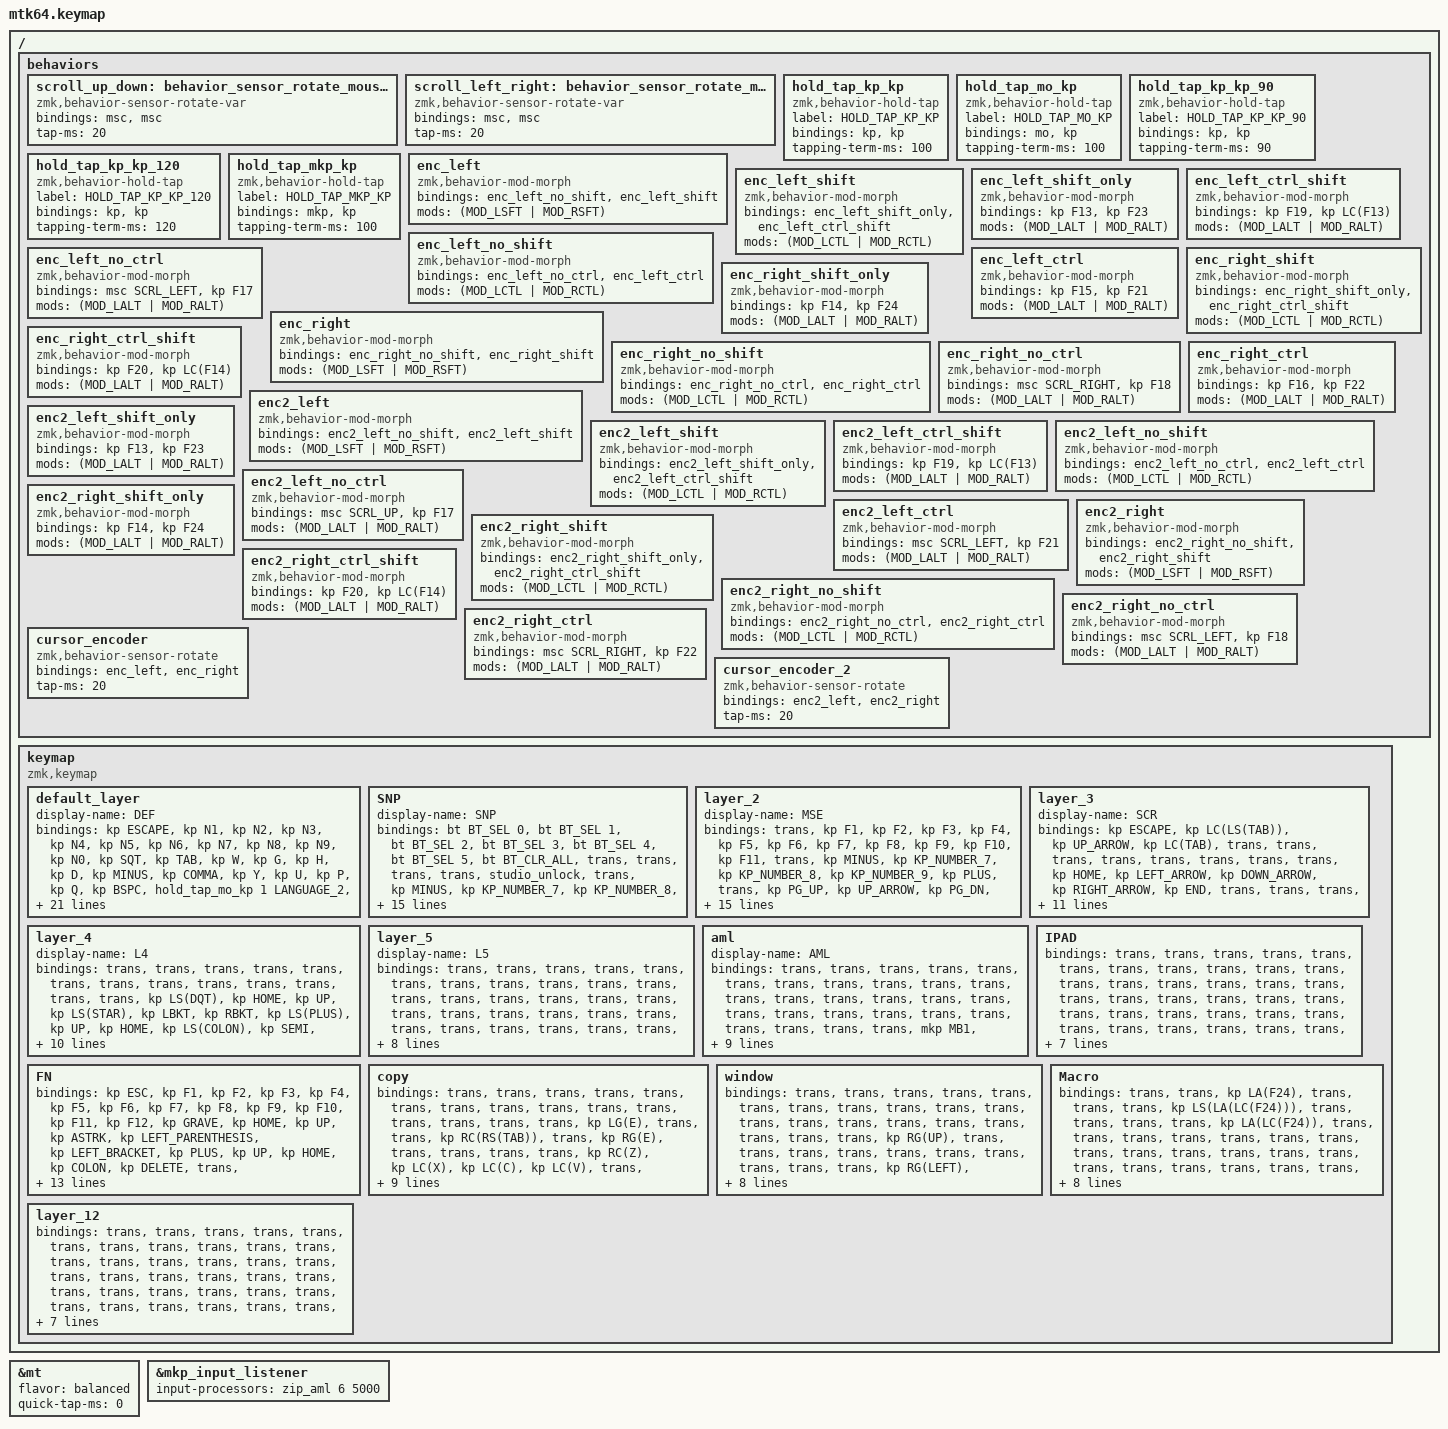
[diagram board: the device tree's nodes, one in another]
#include <input/processors.dtsi>
#include <dt-bindings/zmk/modifiers.h>
#include <behaviors.dtsi>
#include <dt-bindings/zmk/bt.h>
#include <dt-bindings/zmk/keys.h>
#include <dt-bindings/zmk/pointing.h>
#include "keycode_japanese.h"

// スクロール量の設定

#define ZMK_POINTING_DEFAULT_SCRL_VAL 100

&mt {
    flavor = "balanced";
    quick-tap-ms = <0>;
};

&mkp_input_listener { input-processors = <&zip_aml 6 5000>; };

/ {
    behaviors {
        // 垂直スクロール用のbehaviorの設定

        scroll_up_down: behavior_sensor_rotate_mouse_wheel_up_down {
            compatible = "zmk,behavior-sensor-rotate-var";
            #sensor-binding-cells = <2>;
            bindings = <&msc>, <&msc>;

            tap-ms = <20>; // スクロールのタップ時間
        };

        // 水平スクロール用のbehaviorの設定

        scroll_left_right: behavior_sensor_rotate_mouse_wheel_left_right {
            compatible = "zmk,behavior-sensor-rotate-var";
            #sensor-binding-cells = <2>;
            bindings = <&msc>, <&msc>;

            tap-ms = <20>; // スクロールのタップ時間
        };

        hold_tap_kp_kp: hold_tap_kp_kp {
            compatible = "zmk,behavior-hold-tap";
            label = "HOLD_TAP_KP_KP";
            bindings = <&kp>, <&kp>;

            #binding-cells = <2>;
            tapping-term-ms = <100>;
        };

        hold_tap_mo_kp: hold_tap_mo_kp {
            compatible = "zmk,behavior-hold-tap";
            label = "HOLD_TAP_MO_KP";
            bindings = <&mo>, <&kp>;

            #binding-cells = <2>;
            tapping-term-ms = <100>;
        };

        hold_tap_kp_kp_90: hold_tap_kp_kp_90 {
            compatible = "zmk,behavior-hold-tap";
            label = "HOLD_TAP_KP_KP_90";
            bindings = <&kp>, <&kp>;

            #binding-cells = <2>;
            tapping-term-ms = <90>;
        };

        hold_tap_kp_kp_120: hold_tap_kp_kp_120 {
            compatible = "zmk,behavior-hold-tap";
            label = "HOLD_TAP_KP_KP_120";
            bindings = <&kp>, <&kp>;

            #binding-cells = <2>;
            tapping-term-ms = <120>;
        };

        hold_tap_mkp_kp: hold_tap_mkp_kp {
            compatible = "zmk,behavior-hold-tap";
            label = "HOLD_TAP_MKP_KP";
            bindings = <&mkp>, <&kp>;

            #binding-cells = <2>;
            tapping-term-ms = <100>;
        };

        // ==========================================
        // 左エンコーダー
        // ==========================================
        // 左回転

        enc_left: enc_left {
            compatible = "zmk,behavior-mod-morph";
            #binding-cells = <0>;
            bindings = <&enc_left_no_shift>, <&enc_left_shift>;

            mods = <(MOD_LSFT | MOD_RSFT)>;
        };

        enc_left_shift: enc_left_shift {
            compatible = "zmk,behavior-mod-morph";
            #binding-cells = <0>;
            bindings = <&enc_left_shift_only>, <&enc_left_ctrl_shift>;

            mods = <(MOD_LCTL | MOD_RCTL)>;
        };

        enc_left_shift_only: enc_left_shift_only {
            compatible = "zmk,behavior-mod-morph";
            #binding-cells = <0>;
            bindings = <&kp F13>, <&kp F23>;

            mods = <(MOD_LALT | MOD_RALT)>;
        };

        enc_left_ctrl_shift: enc_left_ctrl_shift {
            compatible = "zmk,behavior-mod-morph";
            #binding-cells = <0>;
            bindings = <&kp F19>, <&kp LC(F13)>;

            mods = <(MOD_LALT | MOD_RALT)>;
        };

        enc_left_no_shift: enc_left_no_shift {
            compatible = "zmk,behavior-mod-morph";
            #binding-cells = <0>;
            bindings = <&enc_left_no_ctrl>, <&enc_left_ctrl>;

            mods = <(MOD_LCTL | MOD_RCTL)>;
        };

        enc_left_no_ctrl: enc_left_no_ctrl {
            compatible = "zmk,behavior-mod-morph";
            #binding-cells = <0>;
            bindings = <&msc SCRL_LEFT>, <&kp F17>;

            mods = <(MOD_LALT | MOD_RALT)>;
        };

        enc_left_ctrl: enc_left_ctrl {
            compatible = "zmk,behavior-mod-morph";
            #binding-cells = <0>;
            bindings = <&kp F15>, <&kp F21>;

            mods = <(MOD_LALT | MOD_RALT)>;
        };

        // 右回転

        enc_right: enc_right {
            compatible = "zmk,behavior-mod-morph";
            #binding-cells = <0>;
            bindings = <&enc_right_no_shift>, <&enc_right_shift>;

            mods = <(MOD_LSFT | MOD_RSFT)>;
        };

        enc_right_shift: enc_right_shift {
            compatible = "zmk,behavior-mod-morph";
            #binding-cells = <0>;
            bindings = <&enc_right_shift_only>, <&enc_right_ctrl_shift>;

            mods = <(MOD_LCTL | MOD_RCTL)>;
        };

        enc_right_shift_only: enc_right_shift_only {
            compatible = "zmk,behavior-mod-morph";
            #binding-cells = <0>;
            bindings = <&kp F14>, <&kp F24>;

            mods = <(MOD_LALT | MOD_RALT)>;
        };

        enc_right_ctrl_shift: enc_right_ctrl_shift {
            compatible = "zmk,behavior-mod-morph";
            #binding-cells = <0>;
            bindings = <&kp F20>, <&kp LC(F14)>;

            mods = <(MOD_LALT | MOD_RALT)>;
        };

        enc_right_no_shift: enc_right_no_shift {
            compatible = "zmk,behavior-mod-morph";
            #binding-cells = <0>;
            bindings = <&enc_right_no_ctrl>, <&enc_right_ctrl>;

            mods = <(MOD_LCTL | MOD_RCTL)>;
        };

        enc_right_no_ctrl: enc_right_no_ctrl {
            compatible = "zmk,behavior-mod-morph";
            #binding-cells = <0>;
            bindings = <&msc SCRL_RIGHT>, <&kp F18>;

            mods = <(MOD_LALT | MOD_RALT)>;
        };

        enc_right_ctrl: enc_right_ctrl {
            compatible = "zmk,behavior-mod-morph";
            #binding-cells = <0>;
            bindings = <&kp F16>, <&kp F22>;

            mods = <(MOD_LALT | MOD_RALT)>;
        };

        // ==========================================
        // 右エンコーダー
        // ==========================================
        // 左回転

        enc2_left: enc2_left {
            compatible = "zmk,behavior-mod-morph";
            #binding-cells = <0>;
            bindings = <&enc2_left_no_shift>, <&enc2_left_shift>;

            mods = <(MOD_LSFT | MOD_RSFT)>;
        };

        enc2_left_shift: enc2_left_shift {
            compatible = "zmk,behavior-mod-morph";
            #binding-cells = <0>;
            bindings = <&enc2_left_shift_only>, <&enc2_left_ctrl_shift>;

            mods = <(MOD_LCTL | MOD_RCTL)>;
        };

        enc2_left_shift_only: enc2_left_shift_only {
            compatible = "zmk,behavior-mod-morph";
            #binding-cells = <0>;
            bindings = <&kp F13>, <&kp F23>;

            mods = <(MOD_LALT | MOD_RALT)>;
        };

        enc2_left_ctrl_shift: enc2_left_ctrl_shift {
            compatible = "zmk,behavior-mod-morph";
            #binding-cells = <0>;
            bindings = <&kp F19>, <&kp LC(F13)>;

            mods = <(MOD_LALT | MOD_RALT)>;
        };

        enc2_left_no_shift: enc2_left_no_shift {
            compatible = "zmk,behavior-mod-morph";
            #binding-cells = <0>;
            bindings = <&enc2_left_no_ctrl>, <&enc2_left_ctrl>;

            mods = <(MOD_LCTL | MOD_RCTL)>;
        };

        enc2_left_no_ctrl: enc2_left_no_ctrl {
            compatible = "zmk,behavior-mod-morph";
            #binding-cells = <0>;
            bindings = <&msc SCRL_UP>, <&kp F17>;

            mods = <(MOD_LALT | MOD_RALT)>;
        };

        enc2_left_ctrl: enc2_left_ctrl {
            compatible = "zmk,behavior-mod-morph";
            #binding-cells = <0>;
            bindings = <&msc SCRL_LEFT>, <&kp F21>;

            mods = <(MOD_LALT | MOD_RALT)>;
        };

        // 右回転

        enc2_right: enc2_right {
            compatible = "zmk,behavior-mod-morph";
            #binding-cells = <0>;
            bindings = <&enc2_right_no_shift>, <&enc2_right_shift>;

            mods = <(MOD_LSFT | MOD_RSFT)>;
        };

        enc2_right_shift: enc2_right_shift {
            compatible = "zmk,behavior-mod-morph";
            #binding-cells = <0>;
            bindings = <&enc2_right_shift_only>, <&enc2_right_ctrl_shift>;

            mods = <(MOD_LCTL | MOD_RCTL)>;
        };

        enc2_right_shift_only: enc2_right_shift_only {
            compatible = "zmk,behavior-mod-morph";
            #binding-cells = <0>;
            bindings = <&kp F14>, <&kp F24>;

            mods = <(MOD_LALT | MOD_RALT)>;
        };

        enc2_right_ctrl_shift: enc2_right_ctrl_shift {
            compatible = "zmk,behavior-mod-morph";
            #binding-cells = <0>;
            bindings = <&kp F20>, <&kp LC(F14)>;

            mods = <(MOD_LALT | MOD_RALT)>;
        };

        enc2_right_no_shift: enc2_right_no_shift {
            compatible = "zmk,behavior-mod-morph";
            #binding-cells = <0>;
            bindings = <&enc2_right_no_ctrl>, <&enc2_right_ctrl>;

            mods = <(MOD_LCTL | MOD_RCTL)>;
        };

        enc2_right_no_ctrl: enc2_right_no_ctrl {
            compatible = "zmk,behavior-mod-morph";
            #binding-cells = <0>;
            bindings = <&msc SCRL_LEFT>, <&kp F18>;

            mods = <(MOD_LALT | MOD_RALT)>;
        };

        enc2_right_ctrl: enc2_right_ctrl {
            compatible = "zmk,behavior-mod-morph";
            #binding-cells = <0>;
            bindings = <&msc SCRL_RIGHT>, <&kp F22>;

            mods = <(MOD_LALT | MOD_RALT)>;
        };

        // ==========================================
        // エンコーダー回転の割り当て
        // ==========================================

        cursor_encoder: cursor_encoder {
            compatible = "zmk,behavior-sensor-rotate";
            #sensor-binding-cells = <0>;
            bindings = <&enc_left>, <&enc_right>;

            tap-ms = <20>;
        };

        cursor_encoder_2: cursor_encoder_2 {
            compatible = "zmk,behavior-sensor-rotate";
            #sensor-binding-cells = <0>;
            bindings = <&enc2_left>, <&enc2_right>;

            tap-ms = <20>;
        };

        //ここまで
    };
};

/ {
    keymap {
        compatible = "zmk,keymap";

        default_layer {
            display-name = "DEF";
            bindings = <
&kp ESCAPE  &kp N1  &kp N2  &kp N3  &kp N4  &kp N5  &kp N6  &kp N7  &kp N8  &kp N9  &kp N0  &kp SQT  &kp TAB  &kp W  &kp G  &kp H  &kp D  &kp MINUS  &kp COMMA  &kp Y  &kp U  &kp P  &kp Q  &kp BSPC  &hold_tap_mo_kp 1 LANGUAGE_2  &hold_tap_kp_kp LCTRL R  &hold_tap_kp_kp LALT S  &hold_tap_kp_kp SPACE N  &kp T  &kp K  &kp DOT  &kp A  &kp E  &hold_tap_kp_kp RALT O  &hold_tap_kp_kp RCTRL I  &kp LANGUAGE_1  &kp LSHFT  &hold_tap_kp_kp LEFT_SHIFT B  &kp J  &kp F  &kp L  &kp M  &hold_tap_mo_kp 9 F7  &kp JP_RBKT  &hold_tap_mo_kp 9 SEMICOLON  &kp V  &kp C  &kp X  &hold_tap_kp_kp RSHFT Z  &kp BSLH  &hold_tap_kp_kp LCTRL NUMBER_0  &kp LGUI  &hold_tap_kp_kp LEFT_SHIFT SPACE  &hold_tap_mo_kp 8 ENTER  &hold_tap_mo_kp 10 RIGHT_WIN  &hold_tap_mo_kp 8 ENTER  &kp JP_CARET  &kp JP_YEN  &trans  &kp LA(LS(LCTRL))  &lt 3 LANG1  &mo 11  &trans  &trans  &hold_tap_mo_kp 8 ENTER  &kp LG(V)  &mo 1  &mo 2  &mo 3  &mo 1  &mo 2  &mo 3  &mo 1  &mo 2  &mo 3
            >;

            sensor-bindings =
                <&cursor_encoder>,
                <&scroll_up_down SCRL_UP SCRL_DOWN>;
        };

        SNP {
            display-name = "SNP";
            bindings = <
&bt BT_SEL 0  &bt BT_SEL 1  &bt BT_SEL 2  &bt BT_SEL 3  &bt BT_SEL 4  &bt BT_SEL 5  &bt BT_CLR_ALL  &trans  &trans  &trans  &trans  &studio_unlock  &trans  &kp MINUS  &kp KP_NUMBER_7  &kp KP_NUMBER_8  &kp KP_NUMBER_9  &kp PLUS  &trans  &kp PG_UP  &kp UP_ARROW  &kp PG_DN  &trans  &scrl_inv_tog  &trans  &kp SLASH  &kp KP_NUMBER_4  &kp KP_NUMBER_5  &kp KP_NUMBER_6  &kp ASTERISK  &kp HOME  &kp LEFT_ARROW  &kp DOWN_ARROW  &kp RIGHT_ARROW  &kp END  &aml_tog  &trans  &mt LEFT_SHIFT KP_NUMBER_0  &kp KP_NUMBER_1  &kp KP_NUMBER_2  &kp KP_NUMBER_3  &kp PERIOD  &kp EQUAL  &mkp MB4  &mkp MB5  &mkp MB1  &mkp MB2  &mkp MB3  &trans  &cpi_inc  &kp NUMBER_1  &trans  &trans  &trans  &trans  &trans  &trans  &cpi_dec  &trans  &trans  &trans  &trans  &trans  &trans  &trans  &trans  &trans  &trans  &trans  &trans  &trans  &trans  &trans  &trans  &trans
            >;
        };

        layer_2 {
            display-name = "MSE";
            bindings = <
&trans  &kp F1  &kp F2  &kp F3  &kp F4  &kp F5  &kp F6  &kp F7  &kp F8  &kp F9  &kp F10  &kp F11  &trans  &kp MINUS  &kp KP_NUMBER_7  &kp KP_NUMBER_8  &kp KP_NUMBER_9  &kp PLUS  &trans  &kp PG_UP  &kp UP_ARROW  &kp PG_DN  &trans  &trans  &trans  &kp SLASH  &kp KP_NUMBER_4  &kp KP_NUMBER_5  &kp KP_NUMBER_6  &kp ASTERISK  &kp HOME  &kp LEFT_ARROW  &kp DOWN_ARROW  &kp RIGHT_ARROW  &kp END  &trans  &trans  &mt LEFT_SHIFT KP_NUMBER_0  &kp KP_NUMBER_1  &kp KP_NUMBER_2  &kp KP_NUMBER_3  &kp PERIOD  &kp EQUAL  &mkp MB4  &mkp MB5  &mkp MB1  &mkp MB2  &mkp MB3  &trans  &trans  &kp NUMBER_2  &trans  &trans  &trans  &trans  &trans  &trans  &trans  &trans  &trans  &trans  &trans  &trans  &trans  &trans  &trans  &trans  &trans  &trans  &trans  &trans  &trans  &trans  &trans  &trans
            >;

            sensor-bindings = <
                &inc_dec_kp TAB LS(TAB) 
                &inc_dec_kp PG_UP PG_DN
            >;
        };

        layer_3 {
            display-name = "SCR";
            bindings = <
&kp ESCAPE  &kp LC(LS(TAB))  &kp UP_ARROW  &kp LC(TAB)  &trans  &trans  &trans  &trans  &trans  &trans  &trans  &trans  &kp HOME  &kp LEFT_ARROW  &kp DOWN_ARROW  &kp RIGHT_ARROW  &kp END  &trans  &trans  &trans  &trans  &trans  &trans  &trans  &kp LEFT_SHIFT  &kp LG(LS(LEFT_ARROW))  &trans  &kp LG(LS(RIGHT_ARROW))  &trans  &trans  &trans  &trans  &trans  &trans  &trans  &trans  &trans  &trans  &trans  &trans  &trans  &trans  &trans  &trans  &trans  &trans  &trans  &trans  &trans  &trans  &kp NUMBER_3  &trans  &trans  &trans  &trans  &trans  &trans  &trans
            >;

            sensor-bindings = <
                &scroll_left_right SCRL_LEFT SCRL_RIGHT
                &scroll_up_down SCRL_UP SCRL_DOWN
            >;
        };

        layer_4 {
            display-name = "L4";
            bindings = <
&trans  &trans  &trans  &trans  &trans  &trans  &trans  &trans  &trans  &trans  &trans  &trans  &trans  &kp LS(DQT)  &kp HOME  &kp UP  &kp LS(STAR)  &kp LBKT  &kp RBKT  &kp LS(PLUS)  &kp UP  &kp HOME  &kp LS(COLON)  &kp SEMI  &trans  &kp SQT  &kp LEFT  &kp DOWN  &kp RIGHT  &kp LS(LPAR)  &kp N9  &kp LEFT  &kp DOWN  &kp RIGHT  &kp SEMI  &trans  &trans  &trans  &kp END  &kp EQUAL  &kp FSLH  &kp LS(EXCL)  &kp N1  &trans  &kp QUESTION  &kp MINUS  &kp EQUAL  &kp END  &kp A  &trans  &kp NUMBER_4  &trans  &trans  &trans  &trans  &trans  &trans  &trans  &trans  &trans  &trans  &trans  &trans  &trans  &trans  &trans  &trans  &trans  &trans  &trans  &trans  &trans  &trans  &trans  &trans
            >;
        };

        layer_5 {
            display-name = "L5";
            bindings = <
&trans  &trans  &trans  &trans  &trans  &trans  &trans  &trans  &trans  &trans  &trans  &trans  &trans  &trans  &trans  &trans  &trans  &trans  &trans  &trans  &trans  &trans  &trans  &trans  &trans  &trans  &trans  &trans  &trans  &trans  &trans  &trans  &trans  &trans  &trans  &trans  &trans  &trans  &trans  &trans  &trans  &trans  &trans  &trans  &trans  &trans  &trans  &trans  &trans  &trans  &kp N5  &trans  &trans  &trans  &trans  &trans  &trans  &trans  &trans  &trans  &trans  &trans  &trans  &trans  &trans  &trans  &trans  &trans  &trans  &trans  &trans  &trans  &trans  &trans  &trans
            >;
        };

        aml {
            display-name = "AML";
            bindings = <
&trans  &trans  &trans  &trans  &trans  &trans  &trans  &trans  &trans  &trans  &trans  &trans  &trans  &trans  &trans  &trans  &trans  &trans  &trans  &trans  &trans  &trans  &trans  &trans  &trans  &trans  &trans  &mkp MB1  &mkp MB2  &trans  &trans  &mkp MB1  &mkp MB2  &trans  &mo 1  &trans  &trans  &trans  &mkp MB4  &mkp MB3  &mkp MB5  &trans  &trans  &trans  &trans  &mkp MB4  &mkp MB3  &mkp MB5  &trans  &trans  &kp NUMBER_6  &trans  &trans  &trans  &trans  &trans  &trans  &trans  &trans  &trans  &trans  &trans  &trans  &trans  &trans  &trans  &trans  &trans  &trans  &trans  &trans  &trans  &trans  &trans  &trans
            >;
        };

        IPAD {
            bindings = <
&trans  &trans  &trans  &trans  &trans  &trans  &trans  &trans  &trans  &trans  &trans  &trans  &trans  &trans  &trans  &trans  &trans  &trans  &trans  &trans  &trans  &trans  &trans  &trans  &trans  &trans  &trans  &trans  &trans  &trans  &trans  &trans  &trans  &trans  &trans  &trans  &trans  &trans  &trans  &trans  &trans  &trans  &trans  &trans  &trans  &trans  &trans  &trans  &trans  &trans  &kp N7  &trans  &trans  &trans  &trans  &trans  &trans  &trans  &trans  &trans  &trans  &trans  &trans  &trans  &trans  &trans  &trans  &trans  &trans  &trans  &trans  &trans  &trans  &trans  &trans
            >;
        };

        FN {
            bindings = <
&kp ESC  &kp F1  &kp F2  &kp F3  &kp F4  &kp F5  &kp F6  &kp F7  &kp F8  &kp F9  &kp F10  &kp F11  &kp F12  &kp GRAVE  &kp HOME  &kp UP  &kp ASTRK  &kp LEFT_PARENTHESIS  &kp LEFT_BRACKET  &kp PLUS  &kp UP  &kp HOME  &kp COLON  &kp DELETE  &trans  &hold_tap_kp_kp LCTRL TILDE  &kp LEFT  &kp DOWN  &kp RIGHT_ARROW  &kp RIGHT_PARENTHESIS  &kp RIGHT_BRACKET  &kp LEFT  &kp DOWN  &kp RIGHT  &hold_tap_kp_kp RCTRL SEMICOLON  &trans  &trans  &kp LEFT_SHIFT  &kp END  &kp EQUAL  &kp FSLH  &kp EXCLAMATION  &trans  &trans  &kp QUESTION  &kp MINUS  &kp EQUAL  &kp END  &kp RSHIFT  &trans  &kp N8  &trans  &trans  &trans  &trans  &trans  &trans  &trans  &trans  &trans  &trans  &trans  &trans  &trans  &trans  &trans  &trans  &trans  &trans  &trans  &trans  &trans  &trans  &trans  &trans
            >;
        };

        copy {
            bindings = <
&trans  &trans  &trans  &trans  &trans  &trans  &trans  &trans  &trans  &trans  &trans  &trans  &trans  &trans  &trans  &kp LG(E)  &trans  &trans  &kp RC(RS(TAB))  &trans  &kp RG(E)  &trans  &trans  &trans  &trans  &kp RC(Z)  &kp LC(X)  &kp LC(C)  &kp LC(V)  &trans  &kp LC(TAB)  &kp LC(V)  &kp RC(C)  &kp RC(X)  &kp RC(Z)  &trans  &trans  &trans  &trans  &trans  &trans  &trans  &trans  &trans  &trans  &kp C_PREV  &kp C_PP  &kp LS(C_NEXT)  &trans  &trans  &kp N9  &trans  &trans  &trans  &trans  &trans  &trans  &trans  &trans  &trans  &trans  &trans  &trans  &trans  &trans  &trans  &trans  &trans  &trans  &trans  &trans  &trans  &trans  &trans  &trans
            >;
        };

        window {
            bindings = <
&trans  &trans  &trans  &trans  &trans  &trans  &trans  &trans  &trans  &trans  &trans  &trans  &trans  &trans  &trans  &trans  &trans  &trans  &trans  &trans  &kp RG(UP)  &trans  &trans  &trans  &trans  &trans  &trans  &trans  &trans  &trans  &trans  &kp RG(LEFT)  &kp RG(DOWN)  &kp RG(RIGHT)  &trans  &trans  &trans  &trans  &trans  &trans  &trans  &trans  &trans  &trans  &trans  &trans  &trans  &trans  &trans  &trans  &kp N0  &trans  &trans  &trans  &trans  &trans  &trans  &trans  &trans  &trans  &trans  &trans  &trans  &trans  &trans  &trans  &trans  &trans  &trans  &trans  &trans  &trans  &trans  &trans  &trans
            >;
        };

        Macro {
            bindings = <
&trans  &trans  &kp LA(F24)  &trans  &trans  &trans  &kp LS(LA(LC(F24)))  &trans  &trans  &trans  &trans  &kp LA(LC(F24))  &trans  &trans  &trans  &trans  &trans  &trans  &trans  &trans  &trans  &trans  &trans  &trans  &trans  &trans  &trans  &trans  &trans  &trans  &trans  &trans  &trans  &trans  &trans  &trans  &trans  &trans  &trans  &trans  &trans  &trans  &trans  &trans  &trans  &trans  &trans  &trans  &trans  &trans  &kp B  &trans  &trans  &trans  &trans  &trans  &trans  &trans  &trans  &trans  &trans  &trans  &trans  &trans  &trans  &trans  &kp A  &trans  &trans  &trans  &trans  &trans  &trans  &trans  &trans
            >;
        };

        layer_12 {
            bindings = <
&trans  &trans  &trans  &trans  &trans  &trans  &trans  &trans  &trans  &trans  &trans  &trans  &trans  &trans  &trans  &trans  &trans  &trans  &trans  &trans  &trans  &trans  &trans  &trans  &trans  &trans  &trans  &trans  &trans  &trans  &trans  &trans  &trans  &trans  &trans  &trans  &trans  &trans  &trans  &trans  &trans  &trans  &trans  &trans  &trans  &trans  &trans  &trans  &trans  &trans  &trans  &trans  &trans  &trans  &trans  &trans  &trans  &trans  &trans  &trans  &trans  &trans  &trans  &trans  &trans  &trans  &trans  &trans  &trans  &trans  &trans  &trans  &trans  &trans  &trans
            >;
        };
    };
};
